# nrf54h20_engb_sysctrl register map
Vendor: Nordic Semiconductor; Series: nRF54h; File version: 1
Registers are 32-bit, read-write, reset 0x0 unless marked. A register's access mark holds for its fields unless they carry their own. Offsets are from the block's base; [hi:lo] are bit positions; lines under a group give offsets from that group; 'fields as' and 'values as' point back to an identical list.

## VREGAO1V8 — VREGAO1V8 peripheral
Base 0x5F962000
0x100 EVENTS_READY — Power up done
  [0] EVENTS_READY
    0=NotGenerated (Event not generated); 1=Generated (Event generated)
0x104 EVENTS_SETTLED — Settled flag for MODE handshake
  [0] EVENTS_SETTLED
    values as EVENTS_READY.EVENTS_READY
0x108 EVENTS_IOUTCMP — Analog current comparator
  [0] EVENTS_IOUTCMP
    values as EVENTS_READY.EVENTS_READY
0x10C EVENTS_LP2HP — Current consumption above threshold
  [0] EVENTS_LP2HP
    values as EVENTS_READY.EVENTS_READY
0x110 EVENTS_HP2LP — Current consumption below threshold
  [0] EVENTS_HP2LP
    values as EVENTS_READY.EVENTS_READY
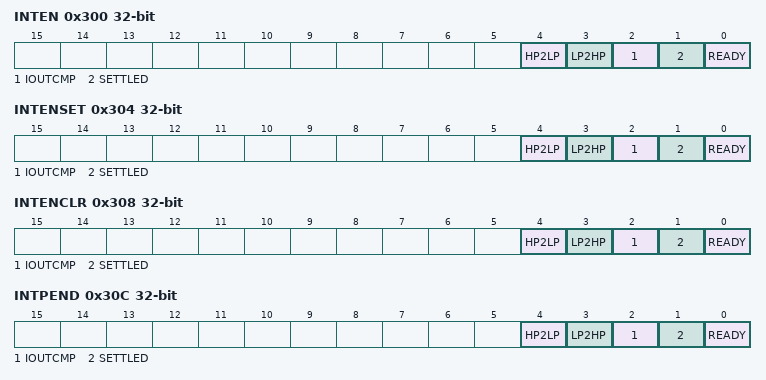
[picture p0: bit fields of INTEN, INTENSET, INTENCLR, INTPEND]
0x300 INTEN — Enable or disable interrupt
  [all] fields
    0=Disabled; 1=Enabled
  [4] HP2LP — Enable or disable interrupt for event HP2LP
  [3] LP2HP — Enable or disable interrupt for event LP2HP
  [2] IOUTCMP — Enable or disable interrupt for event IOUTCMP
  [1] SETTLED — Enable or disable interrupt for event SETTLED
  [0] READY — Enable or disable interrupt for event READY
0x304 INTENSET — Enable interrupt
  [all] fields
    on read: 0=Disabled (Read: Disabled); 1=Enabled (Read: Enabled) | on write: 1=Set (Enable)
  [4] HP2LP — Write '1' to enable interrupt for event HP2LP
  [3] LP2HP — Write '1' to enable interrupt for event LP2HP
  [2] IOUTCMP — Write '1' to enable interrupt for event IOUTCMP
  [1] SETTLED — Write '1' to enable interrupt for event SETTLED
  [0] READY — Write '1' to enable interrupt for event READY
0x308 INTENCLR — Disable interrupt
  [all] fields
    on read: 0=Disabled (Read: Disabled); 1=Enabled (Read: Enabled) | on write: 1=Clear (Disable)
  [4] HP2LP — Write '1' to disable interrupt for event HP2LP
  [3] LP2HP — Write '1' to disable interrupt for event LP2HP
  [2] IOUTCMP — Write '1' to disable interrupt for event IOUTCMP
  [1] SETTLED — Write '1' to disable interrupt for event SETTLED
  [0] READY — Write '1' to disable interrupt for event READY
0x30C INTPEND ro — Pending interrupts
  [all] fields
    on read: 0=NotPending (Read: Not pending); 1=Pending (Read: Pending)
  [4] HP2LP — Read pending status of interrupt for event HP2LP
  [3] LP2HP — Read pending status of interrupt for event LP2HP
  [2] IOUTCMP — Read pending status of interrupt for event IOUTCMP
  [1] SETTLED — Read pending status of interrupt for event SETTLED
  [0] READY — Read pending status of interrupt for event READY
0x400 STATUS ro — Voltage regulator status
  [1:0] MODE — Current voltage regulator mode
    0=High power mode; 1=Low power refresh mode; 2=Ultra-low power refresh mode; 3=Low Power Refresh Differential 5v0 and 1v8
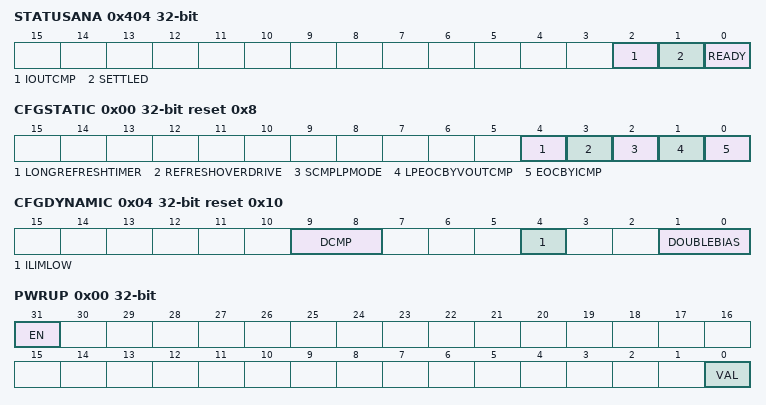
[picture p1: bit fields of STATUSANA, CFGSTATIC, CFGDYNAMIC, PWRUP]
0x404 STATUSANA ro — Status of analog module output signals
  [2] IOUTCMP — Current value of the ICMP signal from the analog module
  [1] SETTLED — Current value of the SETTLED signal from the analog module
  [0] READY — Current value of the READY signal from the analog module
0x410 CONFIG group — Unspecified
  0x00 CFGSTATIC reset 0x8 — VREGAO1V8 static CFG configuration
    [all] fields
      0=Disabled (Configuration disabled); 1=Enabled (Configuration enabled)
    [4] LONGREFRESHTIMER — Configuration for Long refresh timer
    [3] REFRESHOVERDRIVE — Configuration for 10mV refresh overdrive
    [2] SCMPLPMODE — Configuration for SCMP in LP mode
    [1] LPEOCBYVOUTCMP — Configuration for LP EOC BY VOUTCMP
    [0] EOCBYICMP — Configuration for EOC by ICMP
  0x04 CFGDYNAMIC reset 0x10 — VREGAO1V8 dynamic CFG configuration
    [9:8] DCMP — Configuration for DCMP (differential comparator) and LPD mode
      0=Automatically handled by the peripheral; 1=Disabled (Configuration disabled); 2=Enabled (Configuration enabled)
    [4] ILIMLOW — Current limit low configuration for the voltage regulator
      values as the fields of CONFIG.CFGSTATIC
    [1:0] DOUBLEBIAS — Double bias current configuration for the voltage regulator
      values as DCMP
0x440 TRIM group — Unspecified
  0x00 IREF reset 0x8 — Local current reference trimming
    [6:0] VAL — Current reference trimming value
  0x04 VREF reset 0x2 — Reference voltage trim
    [3:0] VAL — Voltage trimming value
  0x08 LOWPOWER — Low power mode output comparator trimming
    [3:0] VAL — Voltage trimming value.
  0x0C LOWPOWERDIFF — Low power differential mode output comparator trimming
    [1:0] VAL — Voltage trimming value.
      1=21mV (Unspecified); 0=27mV (Unspecified); 3=33mV (Unspecified); 2=39mV (Unspecified)
0x480 MIRROR reset 0x1 — Enable LOCK for mirrored registers
  [0] LOCK — Lock for mirrored registers
    0=Disabled (Lock disabled); 1=Enabled (Lock enabled)
0x484 VOUTHPNOMINAL reset 0x4 — Nominal high power mode output voltage programming
  [2:0] VAL — Output voltage value
0x488 VOUTHPHELPER reset 0x2 — High power helper mode output voltage programming
  [2:0] VAL — Output voltage value
0x48C VOUTLP reset 0x4 — Low power mode output voltage programming
  [2:0] VAL — Output voltage value
0x490 MODE — Voltage regulator mode
  [2:0] MODE
    0=Automatically handled by the peripheral; 1=High power mode; 2=Low power refresh mode; 3=Ultra-low power refresh mode; 4=Low Power Refresh Differential 5v0 and 1v8
0x494 ITHRESHOLD reset 0xA — Current threshold for mode transistion
  [3:0] VAL — Current consumption
0x500 OVERRIDE group — Unspecified
  0x00 PWRUP — Override the PWRUP signal to the analog module
    [31] EN — Enable the override
      0=Disabled (Override is disabled); 1=Enabled (Override is enabled)
    [0] VAL — Override value for the signal
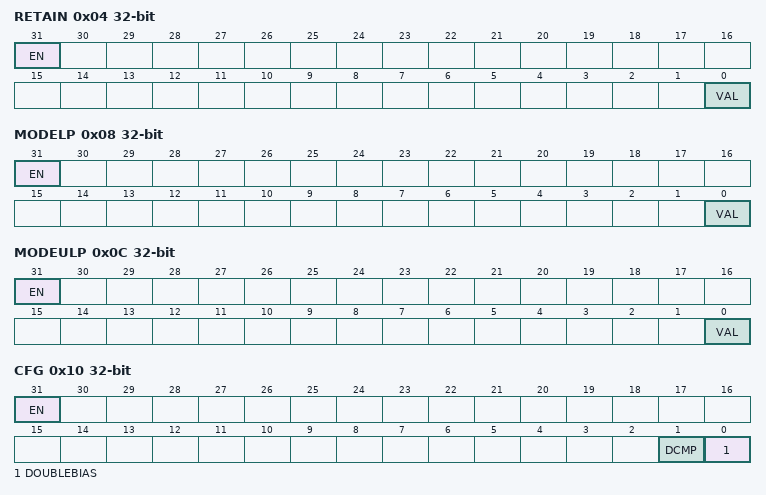
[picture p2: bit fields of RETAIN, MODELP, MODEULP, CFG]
  0x04 RETAIN — Override the RETAIN signal to the analog module
    fields as OVERRIDE.PWRUP
  0x08 MODELP — Override the MODE LP signal to the analog module
    fields as OVERRIDE.PWRUP
  0x0C MODEULP — Override the MODE ULP signal to the analog module
    fields as OVERRIDE.PWRUP
  0x10 CFG — Override the dynamic config signals to the analog module
    [31] EN — Enable the override
      values as OVERRIDE.PWRUP.EN
    [1] DCMP — Override value for the signal
    [0] DOUBLEBIAS — Override value for the signal
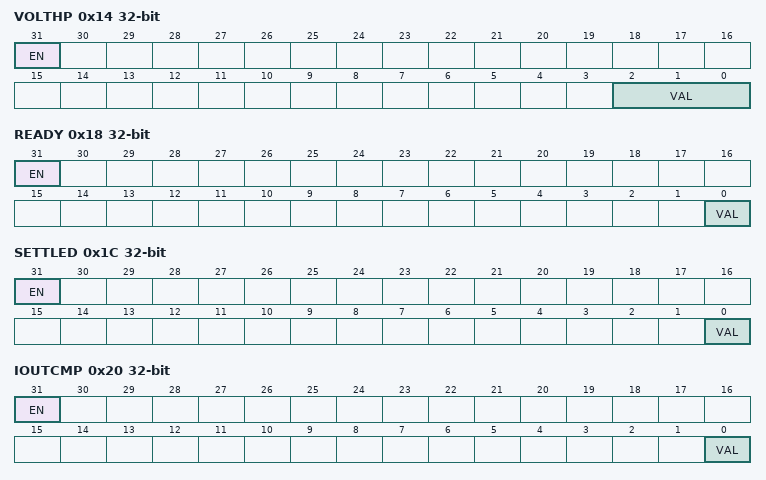
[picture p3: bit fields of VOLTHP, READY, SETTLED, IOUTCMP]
  0x14 VOLTHP — Override the VOLT HP signal to the analog module
    [31] EN — Enable the override
      values as OVERRIDE.PWRUP.EN
    [2:0] VAL — Override value for the signal
  0x18 READY — Override the READY signal from the analog module
    [31] EN — Enable the override
      values as OVERRIDE.PWRUP.EN
    [0] VAL — Current value of the signal
  0x1C SETTLED — Override the SETTLED signal from the analog module
    fields as OVERRIDE.READY
  0x20 IOUTCMP — Override the ICMP signal from the analog module
    fields as OVERRIDE.READY
0x600 DFT group — Unspecified
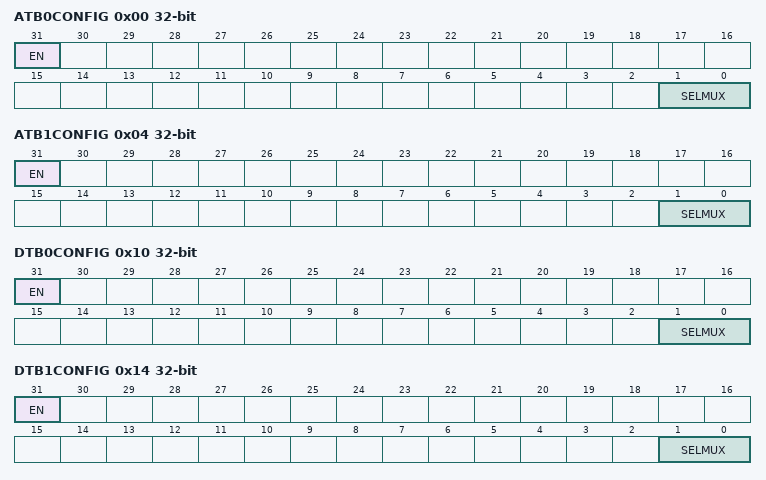
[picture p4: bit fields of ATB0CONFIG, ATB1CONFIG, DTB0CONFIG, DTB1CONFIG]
  0x00 ATB0CONFIG — Analog Test Bus 0 (ATB0) configuration
    [31] EN — Enable the analog test bus
      0=Disabled (Analog test bus is disabled); 1=Enabled (Analog test bus is enabled)
    [1:0] SELMUX — Select multiplexer for ATB0
      0=Ibpsr8u (Internal 8uA current reference); 1=VddSw1v8; 2=Ibpp50n; 3=VSS
  0x04 ATB1CONFIG — Analog Test Bus 1 (ATB1) configuration
    [31] EN — Enable the analog test bus
      values as DFT.ATB0CONFIG.EN
    [1:0] SELMUX — Select multiplexer for ATB1
      0=Vdd1V8fb (Internal direct feedback voltage); 1=Vref0v9Dvt; 2=BufferedVref0V9; 3=BufferedVfb0V9
  0x10 DTB0CONFIG — Digital Test Bus 0 (DTB0) configuration
    [31] EN — Enable the digital test bus
      0=Disabled (Digital test bus is disabled); 1=Enabled (Digital test bus is enabled)
    [1:0] SELMUX — Select multiplexer for DTB0
      0=PwrupIbpp; 1=PwrupIbpsr; 2=ModeLp; 3=VoutCmp
  0x14 DTB1CONFIG — Digital Test Bus 1 (DTB1) configuration
    [31] EN — Enable the digital test bus
      values as DFT.DTB0CONFIG.EN
    [1:0] SELMUX — Select multiplexer for DTB1
      0=SettledIbpp; 1=ReadyIbpsr; 2=ModeUlp; 3=VoutCmpd
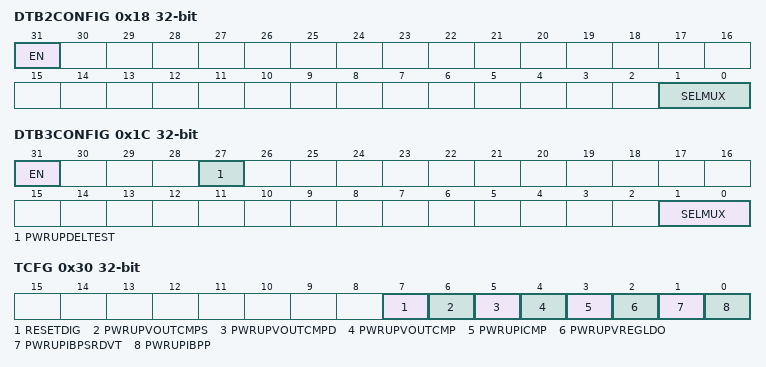
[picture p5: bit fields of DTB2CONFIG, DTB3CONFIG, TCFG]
  0x18 DTB2CONFIG — Digital Test Bus 2 (DTB2) configuration
    [31] EN — Enable the digital test bus
      values as DFT.DTB0CONFIG.EN
    [1:0] SELMUX — Select multiplexer for DTB2
      0=PwrupVregLdo; 1=SettledIbpsr; 2=SettledLdo; 3=VoutCmps
  0x1C DTB3CONFIG — Digital Test Bus 3 (DTB3) configuration
    [31] EN — Enable the digital test bus
      values as DFT.DTB0CONFIG.EN
    [27] PWRUPDELTEST — Enable the PWRUP delay test circuit
      0=Disabled (PWRUP delay test circuit is disabled); 1=Enabled (PWRUP delay test circuit is enabled)
    [1:0] SELMUX — Select multiplexer for DTB3
      0=SetTimer; 1=SettledMbias; 2=ReadyLdo; 3=Icmp5ma
  0x30 TCFG — Test mode configuration
    [all] fields
      0=Disabled (Unspecified); 1=Enabled (Unspecified)
    [7] RESETDIG
    [6] PWRUPVOUTCMPS
    [5] PWRUPVOUTCMPD
    [4] PWRUPVOUTCMP
    [3] PWRUPICMP
    [2] PWRUPVREGLDO
    [1] PWRUPIBPSRDVT
    [0] PWRUPIBPP
